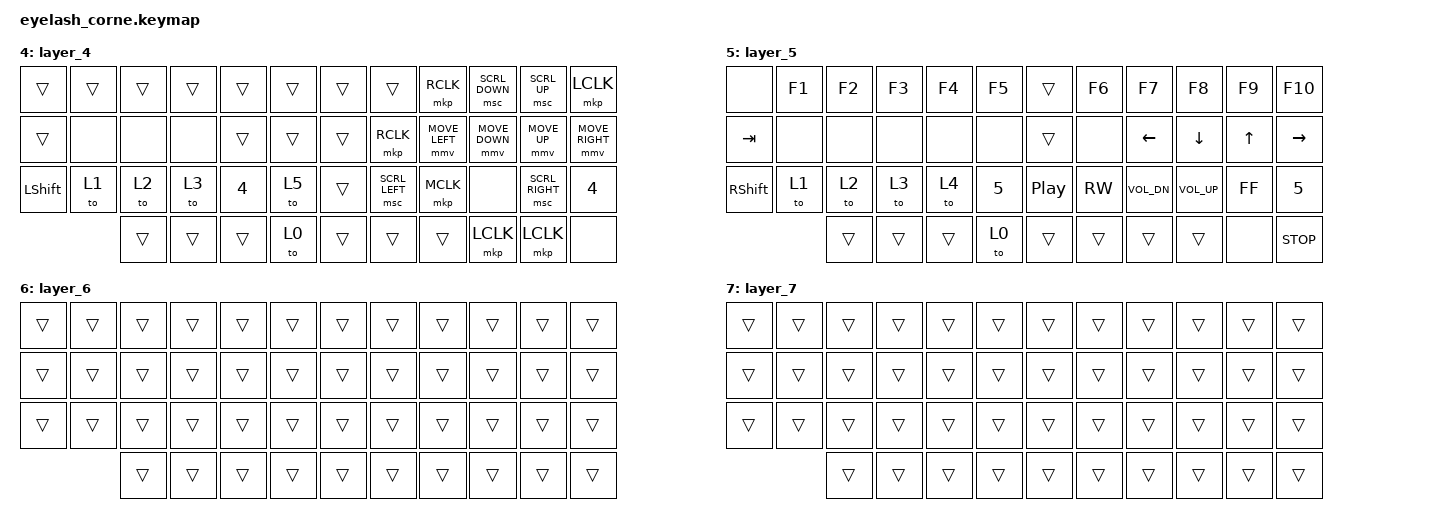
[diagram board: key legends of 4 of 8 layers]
/*
 * Copyright (c) 2020 The ZMK Contributors
 *
 * SPDX-License-Identifier: MIT
 */

#include <behaviors.dtsi>
#include <dt-bindings/zmk/keys.h>
#include <dt-bindings/zmk/bt.h>
#include <dt-bindings/zmk/outputs.h>
#include <dt-bindings/zmk/pointing.h>

/ {
        behaviors {
                scroll_encoder: scroll_encoder {
                        compatible = "zmk,behavior-sensor-rotate";
                        #sensor-binding-cells = <0>;
                        bindings = <&msc SCRL_DOWN>, <&msc SCRL_UP>;
                };
        };

        keymap {
                compatible = "zmk,keymap";
                layer_0 {
                        bindings = <
   &kp ESC &kp Q &kp W &kp E &kp R &kp T &kp RBKT &kp Y &kp U &kp I &kp O &kp P
   &mo 1 &kp A &kp S &kp D &kp F &kp G &kp RCTRL &kp H &kp J &kp K &kp L &kp SEMI
   &kp LGUI &kp Z &none &kp C &kp V &kp B &kp N &kp M &kp COMMA &kp DOT &kp FSLH &kp LBKT
                    &kp LCTRL &mo 3 &kp BSPC &kp DEL &kp RET &lt 2 SPACE
                        >;
                        sensor-bindings = <&scroll_encoder>;
                };
                layer_1 {
                        bindings = <
   &kp TAB &kp LC(LALT) &kp LC(LGUI) &kp LG(LALT) &msc SCRL_UP &mkp LCLK &kp LS(RBKT) &kp 1 &kp HOME &kp PG_DN &kp PG_UP &kp END
   &kp TAB &kp LCTRL &kp LGUI &kp LALT &msc SCRL_DOWN &mkp RCLK &kp LS(0) &kp LS(SEMI) &kp LEFT &kp DOWN &kp UP &kp RIGHT
   &kp RSHIFT &kp LG(Z) &kp LG(X) &kp LG(C) &kp LG(V) &kp LG(Y) &kp FSLH &kp LBKT &kp LS(MINUS) &kp LS(EQUAL) &kp RBKT &kp LS(LBKT)
                    &kp LS(9) &trans &kp RSHIFT &kp LALT &kp RSHIFT &kp TAB
                        >;
                        sensor-bindings = <&scroll_encoder>;
                };
                layer_2 {
                        bindings = <
   &kp TAB &kp 1 &kp 2 &kp 3 &kp 4 &kp 5 &mkp LCLK &kp 6 &kp 7 &kp 8 &kp 9 &kp 0
   &kp TAB &kp LS(1) &kp LS(2) &kp LS(3) &kp LS(4) &kp LS(5) &mkp RCLK &kp LS(6) &kp LS(7) &kp LS(8) &kp LS(9) &kp LS(0)
   &kp LSHIFT &kp F1 &kp F2 &kp F3 &kp F4 &kp F5 &kp F6 &kp F7 &kp F8 &kp F9 &kp F10 &trans
                    &trans &trans &kp BSPC &kp DEL &kp RET
                        >;
                        sensor-bindings = <&scroll_encoder>;
                };
                layer_3 {
                        bindings = <
   &kp TAB &kp LS(1) &kp LS(2) &kp LS(3) &kp LS(4) &kp LS(5) &kp LS(5) &kp LS(LBKT) &kp LBKT &kp LS(9) &kp LS(0) &kp RBKT
   &trans &trans &trans &trans &trans &trans &kp LS(SEMI) &kp KP_PLUS &kp KP_MULTIPLY &kp LS(MINUS) &kp MINUS &kp KP_SLASH
   &kp LSHIFT &kp LC(Z) &kp LC(X) &kp LC(C) &kp LC(V) &kp LC(Y) &kp LS(7) &kp GRAVE &kp BSLH &kp FSLH &kp LS(1) &trans
                    &trans &trans &trans &trans &kp RET
                        >;
                        sensor-bindings = <&scroll_encoder>;
                };
                layer_4 {
                        bindings = <
   &trans &trans &trans &trans &trans &trans &trans &trans &mkp RCLK &msc SCRL_DOWN &msc SCRL_UP &mkp LCLK
   &trans &none /* KC_ACL2 */ &none /* KC_ACL1 */ &none /* KC_ACL0 */ &trans &trans &trans &mkp RCLK &mmv MOVE_LEFT &mmv MOVE_DOWN &mmv MOVE_UP &mmv MOVE_RIGHT
   &kp LSHIFT &to 1 &to 2 &to 3 &kp 4 &to 5 &trans &msc SCRL_LEFT &mkp MCLK &none /* KC_BTN4 */ &msc SCRL_RIGHT &kp 4
                    &trans &trans &trans &to 0 &trans &trans &trans &mkp LCLK &mkp LCLK &none /* KC_BTN5 */
                        >;
                        sensor-bindings = <&scroll_encoder>;
                };
                layer_5 {
                        bindings = <
   &none /* KC_ESCAPE */ &kp F1 &kp F2 &kp F3 &kp F4 &kp F5 &trans &kp F6 &kp F7 &kp F8 &kp F9 &kp F10
   &kp TAB &none /* KC_UNDO */ &none /* KC_CUT */ &none /* KC_COPY */ &none /* KC_PSTE */ &none /* KC_AGIN */ &trans &none /* KC_PSTE */ &kp LEFT &kp DOWN &kp UP &kp RIGHT
   &kp RSHIFT &to 1 &to 2 &to 3 &to 4 &kp 5 &kp C_PP &kp C_RW &kp C_VOL_DN &kp C_VOL_UP &kp C_FF &kp 5
                    &trans &trans &trans &to 0 &trans &trans &trans &trans &none /* KC_COPY */ &kp C_STOP
                        >;
                        sensor-bindings = <&scroll_encoder>;
                };
                layer_6 {
                        bindings = <
   &trans &trans &trans &trans &trans &trans &trans &trans &trans &trans &trans &trans
   &trans &trans &trans &trans &trans &trans &trans &trans &trans &trans &trans &trans
   &trans &trans &trans &trans &trans &trans &trans &trans &trans &trans &trans &trans
                    &trans &trans &trans &trans &trans &trans &trans &trans &trans &trans
                        >;
                        sensor-bindings = <&scroll_encoder>;
                };
                layer_7 {
                        bindings = <
   &trans &trans &trans &trans &trans &trans &trans &trans &trans &trans &trans &trans
   &trans &trans &trans &trans &trans &trans &trans &trans &trans &trans &trans &trans
   &trans &trans &trans &trans &trans &trans &trans &trans &trans &trans &trans &trans
                    &trans &trans &trans &trans &trans &trans &trans &trans &trans &trans
                        >;
                        sensor-bindings = <&scroll_encoder>;
                };
        };
};
